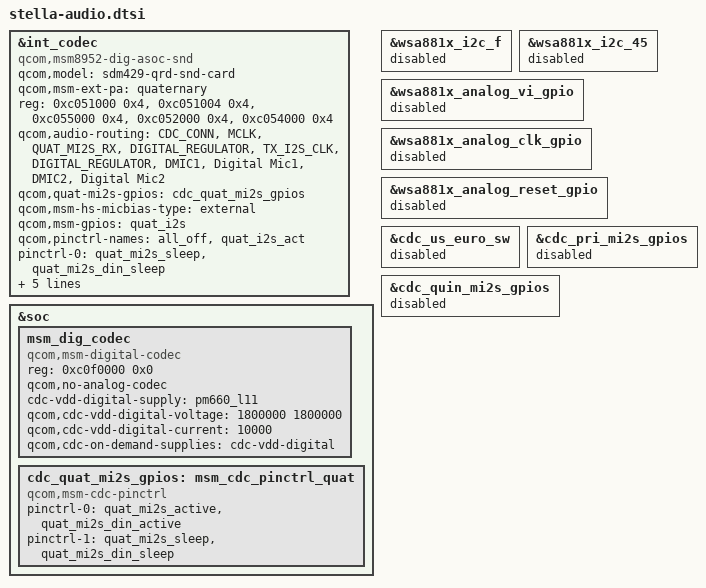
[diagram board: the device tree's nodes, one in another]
/*
 * Copyright (c) 2019, The Linux Foundation. All rights reserved.
 *
 * This program is free software; you can redistribute it and/or modify
 * it under the terms of the GNU General Public License version 2 and
 * only version 2 as published by the Free Software Foundation.
 *
 * This program is distributed in the hope that it will be useful,
 * but WITHOUT ANY WARRANTY; without even the implied warranty of
 * MERCHANTABILITY or FITNESS FOR A PARTICULAR PURPOSE.  See the
 * GNU General Public License for more details.
 */

&int_codec {
	compatible = "qcom,msm8952-dig-asoc-snd";
	status = "okay";
	qcom,model = "sdm429-qrd-snd-card";
	qcom,msm-ext-pa = "quaternary";
	reg = <0xc051000 0x4>,
		<0xc051004 0x4>,
		<0xc055000 0x4>,
		<0xc052000 0x4>,
		<0xc054000 0x4>;
	reg-names = "csr_gp_io_mux_mic_ctl",
		"csr_gp_io_mux_spkr_ctl",
		"csr_gp_io_lpaif_pri_pcm_pri_mode_muxsel",
		"csr_gp_io_mux_quin_ctl",
		"csr_gp_io_mux_mic_ext_clk_ctl";
	qcom,audio-routing =
		"CDC_CONN", "MCLK",
		"QUAT_MI2S_RX", "DIGITAL_REGULATOR",
		"TX_I2S_CLK", "DIGITAL_REGULATOR",
		"DMIC1", "Digital Mic1",
		"DMIC2", "Digital Mic2";
	qcom,quat-mi2s-gpios = <&cdc_quat_mi2s_gpios>;
	qcom,msm-hs-micbias-type = "external";
	qcom,msm-gpios =
		"quat_i2s";
	qcom,pinctrl-names =
		"all_off",
		"quat_i2s_act";
	pinctrl-names =
		"all_off",
		"quat_i2s_act";
	pinctrl-0 = <&quat_mi2s_sleep &quat_mi2s_din_sleep>;
	pinctrl-1 = <&quat_mi2s_active &quat_mi2s_din_active>;

	asoc-codec = <&stub_codec>, <&msm_dig_codec>;
	asoc-codec-names = "msm-stub-codec.1", "msm-dig-codec";
};

&soc {
	msm_dig_codec: msm_dig_codec {
		compatible = "qcom,msm-digital-codec";
		reg = <0xc0f0000 0x0>;
		qcom,no-analog-codec;
		cdc-vdd-digital-supply = <&pm660_l11>;
		qcom,cdc-vdd-digital-voltage = <1800000 1800000>;
		qcom,cdc-vdd-digital-current = <10000>;
		qcom,cdc-on-demand-supplies = "cdc-vdd-digital";
	};

	cdc_quat_mi2s_gpios: msm_cdc_pinctrl_quat {
		compatible = "qcom,msm-cdc-pinctrl";
		pinctrl-names = "aud_active", "aud_sleep";
		pinctrl-0 = <&quat_mi2s_active &quat_mi2s_din_active>;
		pinctrl-1 = <&quat_mi2s_sleep &quat_mi2s_din_sleep>;
	};
};

&wsa881x_i2c_f {
	status = "disabled";
};

&wsa881x_i2c_45 {
	status = "disabled";
};

&wsa881x_analog_vi_gpio {
	status = "disabled";
};

&wsa881x_analog_clk_gpio {
	status = "disabled";
};

&wsa881x_analog_reset_gpio {
	status = "disabled";
};

&cdc_us_euro_sw {
	status = "disabled";
};

&cdc_pri_mi2s_gpios {
	status = "disabled";
};

&cdc_quin_mi2s_gpios {
	status = "disabled";
};
